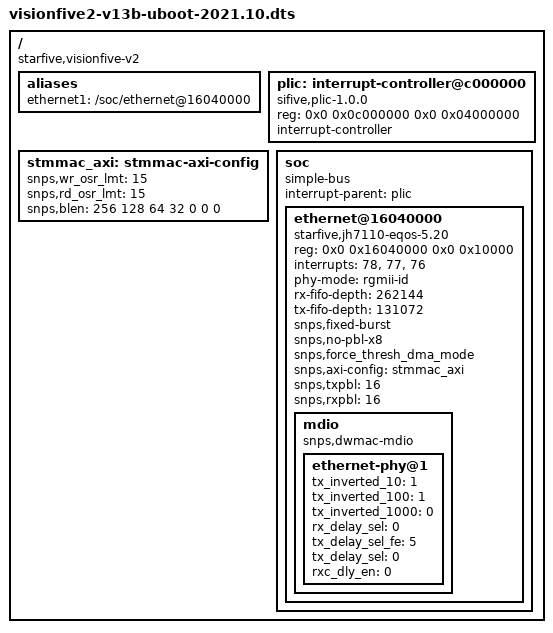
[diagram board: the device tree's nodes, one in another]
/dts-v1/;

/ {
    compatible = "starfive,visionfive-v2", "starfive,jh7110";
    #address-cells = <2>;
    #size-cells = <2>;

    aliases {
        ethernet1 = "/soc/ethernet@16040000";
    };

    plic: interrupt-controller@c000000 {
        compatible = "sifive,plic-1.0.0";
        reg = <0x0 0x0c000000 0x0 0x04000000>;
        interrupt-controller;
        #interrupt-cells = <1>;
    };

    stmmac_axi: stmmac-axi-config {
        snps,wr_osr_lmt = <15>;
        snps,rd_osr_lmt = <15>;
        snps,blen = <256 128 64 32 0 0 0>;
    };

    soc {
        compatible = "simple-bus";
        #address-cells = <2>;
        #size-cells = <2>;
        ranges;
        interrupt-parent = <&plic>;

        ethernet@16040000 {
            compatible = "starfive,jh7110-eqos-5.20", "snps,dwmac-5.20";
            reg = <0x0 0x16040000 0x0 0x10000>;
            interrupts = <78>, <77>, <76>;
            phy-mode = "rgmii-id";
            rx-fifo-depth = <262144>;
            tx-fifo-depth = <131072>;
            snps,fixed-burst;
            snps,no-pbl-x8;
            snps,force_thresh_dma_mode;
            snps,axi-config = <&stmmac_axi>;
            snps,txpbl = <16>;
            snps,rxpbl = <16>;
            status = "okay";

            mdio {
                compatible = "snps,dwmac-mdio";
                #address-cells = <1>;
                #size-cells = <0>;

                ethernet-phy@1 {
                    tx_inverted_10 = <1>;
                    tx_inverted_100 = <1>;
                    tx_inverted_1000 = <0>;
                    rx_delay_sel = <0>;
                    tx_delay_sel_fe = <5>;
                    tx_delay_sel = <0>;
                    rxc_dly_en = <0>;
                };
            };
        };
    };
};
